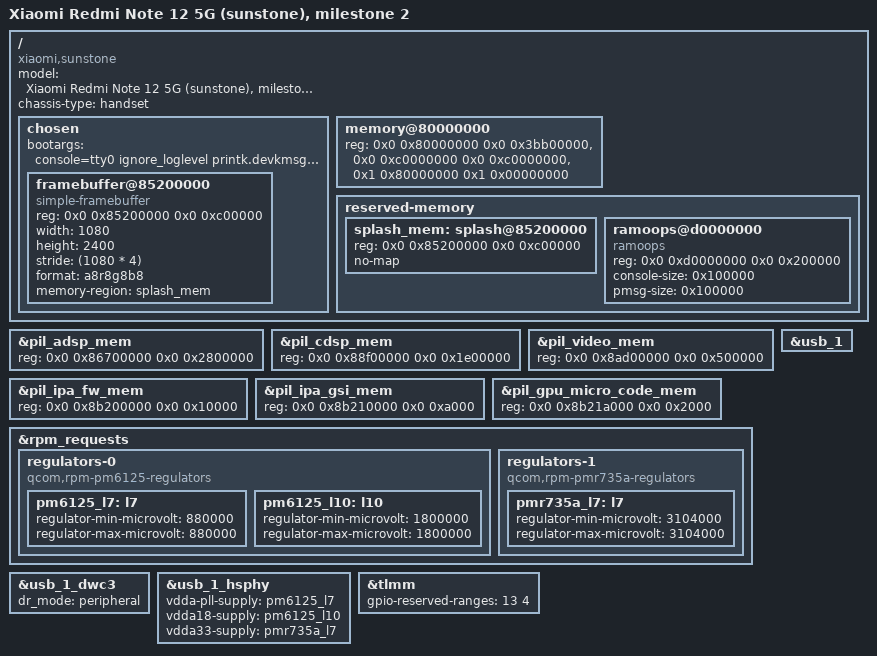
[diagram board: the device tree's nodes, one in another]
// SPDX-License-Identifier: BSD-3-Clause
/*
 * Xiaomi Redmi Note 12 5G (sunstone), SM4375 "blair": milestone 2 tree.
 *
 * Built on mainline's sm6375.dtsi ("holi", the SoC blair derives from: same CPU, GIC, GCC
 * clock/reset indices and USB block as the downstream blair DT). Adds what M2 needs: RPM
 * regulators for the USB HS PHY and the dwc3 controller as a peripheral, so an NCM gadget
 * carries ssh. The splash framebuffer stays on simpledrm; clk_ignore_unused and
 * pd_ignore_unused keep GCC/RPM from switching off the display path ABL left running.
 * Board values from the phone's live DT (2026-10-20).
 */
/dts-v1/;

#include "sm6375.dtsi"

/ {
	model = "Xiaomi Redmi Note 12 5G (sunstone), milestone 2";
	compatible = "xiaomi,sunstone", "qcom,sm4375", "qcom,sm6375";
	chassis-type = "handset";

	chosen {
		#address-cells = <2>;
		#size-cells = <2>;
		ranges;
		bootargs = "console=tty0 ignore_loglevel printk.devkmsg=on panic=20 reboot=warm rdinit=/init clk_ignore_unused pd_ignore_unused";

		framebuffer@85200000 {
			compatible = "simple-framebuffer";
			reg = <0x0 0x85200000 0x0 0xc00000>;
			width = <1080>;
			height = <2400>;
			stride = <(1080 * 4)>;
			format = "a8r8g8b8";
			memory-region = <&splash_mem>;
		};
	};

	memory@80000000 {
		reg = <0x0 0x80000000 0x0 0x3bb00000>,
		      <0x0 0xc0000000 0x0 0xc0000000>,
		      <0x1 0x80000000 0x1 0x00000000>;
	};

	reserved-memory {
		splash_mem: splash@85200000 {
			reg = <0x0 0x85200000 0x0 0xc00000>;
			no-map;
		};

		/* the downstream kernel's layout, so either kernel reads the other's records */
		ramoops@d0000000 {
			compatible = "ramoops";
			reg = <0x0 0xd0000000 0x0 0x200000>;
			console-size = <0x100000>;
			pmsg-size = <0x100000>;
		};
	};
};

/* blair's firmware carve-outs sit higher than holi's from adsp on (live DT) */
&pil_adsp_mem { reg = <0x0 0x86700000 0x0 0x2800000>; };
&pil_cdsp_mem { reg = <0x0 0x88f00000 0x0 0x1e00000>; };
&pil_video_mem { reg = <0x0 0x8ad00000 0x0 0x500000>; };
&pil_ipa_fw_mem { reg = <0x0 0x8b200000 0x0 0x10000>; };
&pil_ipa_gsi_mem { reg = <0x0 0x8b210000 0x0 0xa000>; };
&pil_gpu_micro_code_mem { reg = <0x0 0x8b21a000 0x0 0x2000>; };

&rpm_requests {
	regulators-0 {
		compatible = "qcom,rpm-pm6125-regulators";

		/* USB HS PHY core (downstream qcom,vdd-voltage-level 0.88 V) */
		pm6125_l7: l7 {
			regulator-min-microvolt = <880000>;
			regulator-max-microvolt = <880000>;
		};

		/* USB HS PHY 1.8 V */
		pm6125_l10: l10 {
			regulator-min-microvolt = <1800000>;
			regulator-max-microvolt = <1800000>;
		};
	};

	regulators-1 {
		compatible = "qcom,rpm-pmr735a-regulators";

		/* USB HS PHY 3.1 V */
		pmr735a_l7: l7 {
			regulator-min-microvolt = <3104000>;
			regulator-max-microvolt = <3104000>;
		};
	};
};

&usb_1 {
	status = "okay";
};

&usb_1_dwc3 {
	dr_mode = "peripheral";
};

&usb_1_hsphy {
	vdda-pll-supply = <&pm6125_l7>;
	vdda18-supply = <&pm6125_l10>;
	vdda33-supply = <&pmr735a_l7>;
	status = "okay";
};

&tlmm {
	/* fingerprint SPI (qup10), owned by TZ: reading these aborts (boot-2) */
	gpio-reserved-ranges = <13 4>;
};
